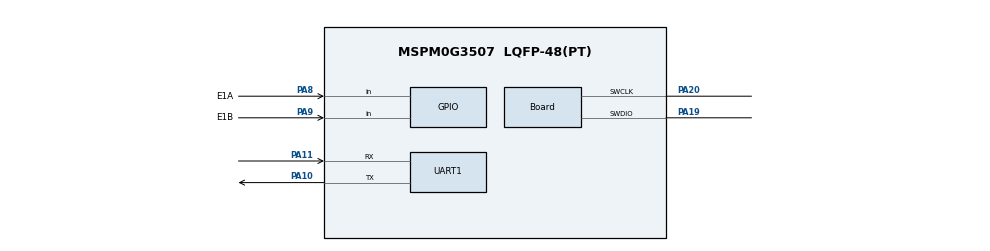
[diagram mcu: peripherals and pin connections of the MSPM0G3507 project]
/**
 * These arguments were used when this file was generated. They will be automatically applied on subsequent loads
 * via the GUI or CLI. Run CLI with '--help' for additional information on how to override these arguments.
 * @cliArgs --device "MSPM0G350X" --part "Default" --package "LQFP-48(PT)" --product "mspm0_sdk@2.04.00.06"
 * @v2CliArgs --device "MSPM0G3507" --package "LQFP-48(PT)" --product "mspm0_sdk@2.04.00.06"
 * @versions {"tool":"1.23.1+4034"}
 */

/**
 * Import the modules used in this configuration.
 */
const GPIO   = scripting.addModule("/ti/driverlib/GPIO", {}, false);
const GPIO1  = GPIO.addInstance();
const SYSCTL = scripting.addModule("/ti/driverlib/SYSCTL");
const TIMER  = scripting.addModule("/ti/driverlib/TIMER", {}, false);
const TIMER1 = TIMER.addInstance();
const UART   = scripting.addModule("/ti/driverlib/UART", {}, false);
const UART1  = UART.addInstance();

/**
 * Write custom configuration values to the imported modules.
 */
const gate7  = system.clockTree["MFCLKGATE"];
gate7.enable = true;

GPIO1.$name                               = "GPIO_ENCODER";
GPIO1.associatedPins.create(2);
GPIO1.associatedPins[0].$name             = "E1A";
GPIO1.associatedPins[0].direction         = "INPUT";
GPIO1.associatedPins[0].interruptEn       = true;
GPIO1.associatedPins[0].interruptPriority = "0";
GPIO1.associatedPins[0].polarity          = "RISE";
GPIO1.associatedPins[0].pin.$assign       = "PA8";
GPIO1.associatedPins[1].$name             = "E1B";
GPIO1.associatedPins[1].direction         = "INPUT";
GPIO1.associatedPins[1].interruptEn       = true;
GPIO1.associatedPins[1].interruptPriority = "0";
GPIO1.associatedPins[1].polarity          = "RISE";
GPIO1.associatedPins[1].pin.$assign       = "PA9";

const Board                       = scripting.addModule("/ti/driverlib/Board", {}, false);
Board.peripheral.$assign          = "DEBUGSS";
Board.peripheral.swclkPin.$assign = "PA20";
Board.peripheral.swdioPin.$assign = "PA19";

SYSCTL.forceDefaultClkConfig = true;
SYSCTL.clockTreeEn           = true;

TIMER1.$name              = "TIMER_TICK";
TIMER1.timerPeriod        = "20 ms";
TIMER1.timerClkDiv        = 8;
TIMER1.timerClkPrescale   = 4;
TIMER1.timerMode          = "PERIODIC";
TIMER1.timerStartTimer    = true;
TIMER1.interrupts         = ["ZERO"];
TIMER1.interruptPriority  = "3";
TIMER1.peripheral.$assign = "TIMG0";

UART1.$name                    = "UART_0";
UART1.uartClkSrc               = "MFCLK";
UART1.enabledInterrupts        = ["RX"];
UART1.peripheral.$assign       = "UART0";
UART1.peripheral.rxPin.$assign = "PA11";
UART1.peripheral.txPin.$assign = "PA10";
UART1.txPinConfig.$name        = "ti_driverlib_gpio_GPIOPinGeneric0";
UART1.rxPinConfig.$name        = "ti_driverlib_gpio_GPIOPinGeneric1";

const ProjectConfig              = scripting.addModule("/ti/project_config/ProjectConfig", {}, false);
ProjectConfig.migrationCondition = true;
